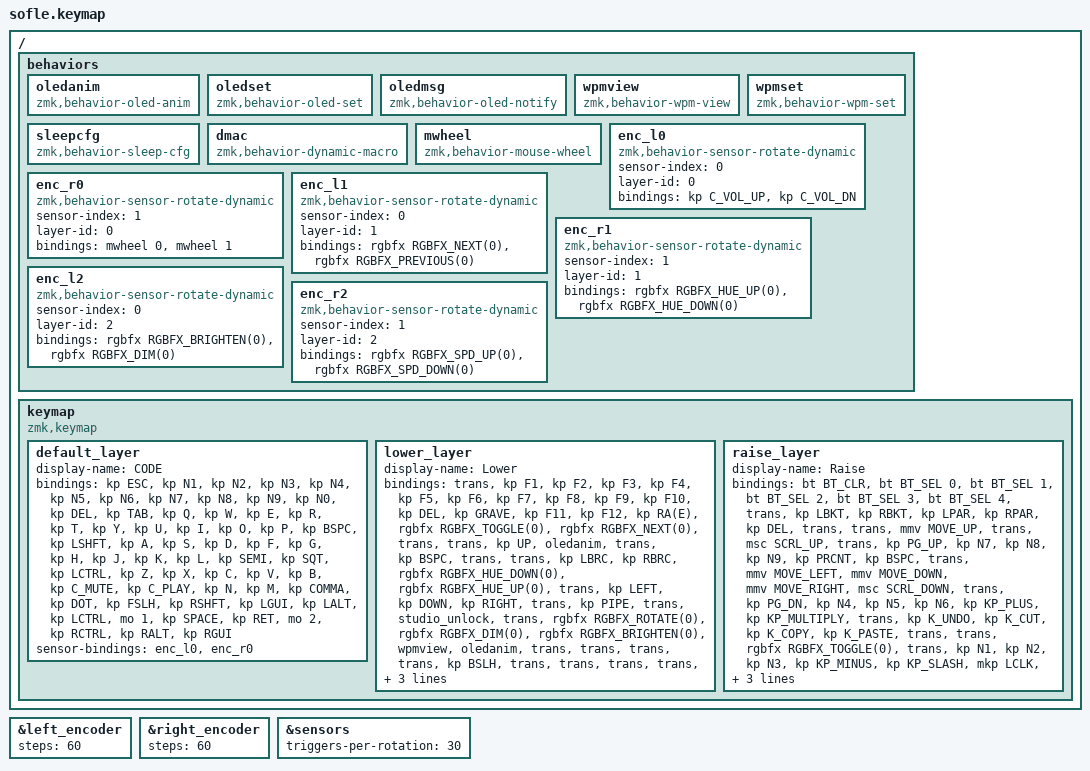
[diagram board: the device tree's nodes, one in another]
/*
 * Copyright (c) 2020 The ZMK Contributors
 *
 * SPDX-License-Identifier: MIT
 */

#include <behaviors.dtsi>
#include <dt-bindings/zmk/keys.h>
#include <dt-bindings/zmk/bt.h>
#include <dt-bindings/zmk/ext_power.h>
#include <dt-bindings/zmk/rgb_fx.h>
/* Raton por teclado (&mmv/&mkp/&msc). Vienen de serie en ZMK con
   CONFIG_ZMK_POINTING, que ya esta activo para la rueda del encoder. */
#include <dt-bindings/zmk/pointing.h>

/*
 * Same layout as the Choc variant (codekeeb/sofle-choc-rgb-zmk):
 * 3 layers, RGB controls on LOWER (left half) and on the encoders
 * (lower = mode/hue, raise = brightness/speed), numpad on RAISE.
 *
 * Unlike the Choc, NO led_strip/spi3 override is needed here: the MX PCB
 * uses P0.06 with a 36-LED chain, which matches what the official sofle
 * shield already sets.
 */

/ {
    behaviors {
        // Cycles the right OLED animation (gem/cat/head/spaceman/pokemon/logo)
        oledanim: oledanim {
            compatible = "zmk,behavior-oled-anim";
            #binding-cells = <0>;
        };

        // Relay interno central->periferico: fija la animacion por
        // indice. No se pone en ninguna tecla; lo invoca el handler RPC
        // de ZMK Studio, igual que el RGB usa &rgbsync. Sin esto, la web
        // cambiaba la animacion solo en la mitad central, que no tiene
        // la pantalla animada, y no se veia nada.
        oledset: oledset {
            compatible = "zmk,behavior-oled-set";
            #binding-cells = <1>;
        };

        // Internal central->peripheral relay: a notice (BT profile, BT
        // clear, USB/BLE, Caps Lock, Studio) for the right screen. Not
        // bound to any key; see src/oled_notify.c.
        oledmsg: oledmsg {
            compatible = "zmk,behavior-oled-notify";
            #binding-cells = <1>;
        };

        // Vista de WPM de la pantalla IZQUIERDA (bongo cat, luna,
        // numero, velocimetro, grafico). &wpmview cicla; &wpmset la
        // fija por indice y lo usa el RPC de ZMK Studio.
        wpmview: wpmview {
            compatible = "zmk,behavior-wpm-view";
            #binding-cells = <0>;
        };

        wpmset: wpmset {
            compatible = "zmk,behavior-wpm-set";
            #binding-cells = <1>;
        };

        // Relay interno central->periferico del ajuste de deep sleep
        // (activado + minutos). Como &oledset, no va en ninguna tecla:
        // lo invoca el handler RPC. Hace falta porque cada mitad vigila
        // su propia inactividad, asi que el ajuste hay que llevarlo a
        // las dos o el periferico se queda con el plazo viejo.
        sleepcfg: sleepcfg {
            compatible = "zmk,behavior-sleep-cfg";
            #binding-cells = <2>;
        };

        // Macros editables en caliente (CODEKEEB PATCH, ver
        // src/behaviors/behavior_dynamic_macro.c). &dmac N reproduce la
        // ranura N, cuyo contenido se escribe desde el editor web y vive
        // en flash: sirve para ñ, tildes, un email, "→"... sin recompilar.
        dmac: dmac {
            compatible = "zmk,behavior-dynamic-macro";
            #binding-cells = <1>;
        };

        // Discrete mouse wheel (CODEKEEB PATCH, see
        // src/behaviors/behavior_mouse_wheel.c). One HID wheel tick per
        // press: &mwheel 0 = up, 1 = down, 2 = left, 3 = right. Unlike
        // ZMK's stock &msc this works when fired from an encoder.
        mwheel: mwheel {
            compatible = "zmk,behavior-mouse-wheel";
            #binding-cells = <1>;
        };

        // Encoder rotation bindings below use zmk,behavior-sensor-rotate-dynamic
        // (CODEKEEB PATCH, see src/behaviors/behavior_sensor_rotate_dynamic.c)
        // instead of the stock zmk,behavior-sensor-rotate: same tap-dispatch
        // mechanism, but the cw/ccw pair is readable and rewritable at
        // runtime over ZMK Studio (persisted in flash), one instance per
        // (layer, encoder) combination. `bindings` below is only the
        // factory/default pair -- editing it live doesn't touch this file.
        // sensor-index: 0 = left encoder, 1 = right encoder.
        // layer-id: matches this keymap's declaration order (no layer
        // reordering used), 0 = CODE, 1 = Lower, 2 = Raise.

        enc_l0: enc_l0 { // CODE layer, left encoder: volume (factory)
            compatible = "zmk,behavior-sensor-rotate-dynamic";
            #sensor-binding-cells = <0>;
            sensor-index = <0>;
            layer-id = <0>;
            bindings = <&kp C_VOL_UP>, <&kp C_VOL_DN>;
        };

        enc_r0: enc_r0 { // CODE layer, right encoder: mouse wheel (factory)
            compatible = "zmk,behavior-sensor-rotate-dynamic";
            #sensor-binding-cells = <0>;
            sensor-index = <1>;
            layer-id = <0>;
            bindings = <&mwheel 0>, <&mwheel 1>;
        };

        enc_l1: enc_l1 { // Lower layer, left encoder: RGB mode (factory)
            compatible = "zmk,behavior-sensor-rotate-dynamic";
            #sensor-binding-cells = <0>;
            sensor-index = <0>;
            layer-id = <1>;
            bindings = <&rgbfx RGBFX_NEXT(0)>, <&rgbfx RGBFX_PREVIOUS(0)>;
        };

        enc_r1: enc_r1 { // Lower layer, right encoder: RGB hue (factory)
            compatible = "zmk,behavior-sensor-rotate-dynamic";
            #sensor-binding-cells = <0>;
            sensor-index = <1>;
            layer-id = <1>;
            bindings = <&rgbfx RGBFX_HUE_UP(0)>, <&rgbfx RGBFX_HUE_DOWN(0)>;
        };

        enc_l2: enc_l2 { // Raise layer, left encoder: RGB brightness (factory)
            compatible = "zmk,behavior-sensor-rotate-dynamic";
            #sensor-binding-cells = <0>;
            sensor-index = <0>;
            layer-id = <2>;
            bindings = <&rgbfx RGBFX_BRIGHTEN(0)>, <&rgbfx RGBFX_DIM(0)>;
        };

        enc_r2: enc_r2 { // Raise layer, right encoder: RGB speed (factory)
            compatible = "zmk,behavior-sensor-rotate-dynamic";
            #sensor-binding-cells = <0>;
            sensor-index = <1>;
            layer-id = <2>;
            bindings = <&rgbfx RGBFX_SPD_UP(0)>, <&rgbfx RGBFX_SPD_DOWN(0)>;
        };
    };

    keymap {
        compatible = "zmk,keymap";

        default_layer {
            display-name = "CODE";
// ------------------------------------------------------------------------------------------------------------------
// |  ESC  |  1  |  2  |  3   |  4   |  5   |                         |  6   |  7    |  8    |  9   |   0   |  DEL  |
// |  TAB  |  Q  |  W  |  E   |  R   |  T   |                         |  Y   |  U    |  I    |  O   |   P   | BKSPC |
// | SHIFT |  A  |  S  |  D   |  F   |  G   |                         |  H   |  J    |  K    |  L   |   ;   |   '   |
// |  CTRL |  Z  |  X  |  C   |  V   |  B   |  MUTE  |        | PLAY  |  N   |  M    |  ,    |  .   |   /   | SHIFT |
//               | GUI | ALT  | CTRL | LOWER|  SPACE |        | ENTER | RAISE| CTRL  | ALT   | GUI  |
            bindings = <
&kp ESC   &kp N1 &kp N2   &kp N3   &kp N4    &kp N5                              &kp N6 &kp N7    &kp N8    &kp N9   &kp N0   &kp DEL
&kp TAB   &kp Q  &kp W    &kp E    &kp R     &kp T                               &kp Y  &kp U     &kp I     &kp O    &kp P    &kp BSPC
&kp LSHFT &kp A  &kp S    &kp D    &kp F     &kp G                               &kp H  &kp J     &kp K     &kp L    &kp SEMI &kp SQT
&kp LCTRL &kp Z  &kp X    &kp C    &kp V     &kp B  &kp C_MUTE       &kp C_PLAY  &kp N  &kp M     &kp COMMA &kp DOT  &kp FSLH &kp RSHFT
                 &kp LGUI &kp LALT &kp LCTRL &mo 1  &kp SPACE        &kp RET     &mo 2  &kp RCTRL &kp RALT  &kp RGUI
            >;

            // Right encoder: real mouse wheel, one HID tick per detent
            // (&mwheel). ZMK's stock &msc can NOT be used here: it only
            // emits from its own delayed work loop and needs the press
            // held across several cycles, while sensor-rotate fires a
            // short tap -- USB logging confirmed zero reports at any
            // tap-ms. behavior_mouse_wheel.c sends one complete wheel
            // event per press instead, which is what a wheel detent
            // actually is. Both slots stay editable live from ZMK Studio
            // (see enc_l0/enc_r0 above).
            sensor-bindings = <&enc_l0 &enc_r0>;
        };

        lower_layer {
            display-name = "Lower";
// TODO: Some binds are waiting for shifted keycode support.
// ------------------------------------------------------------------------------------------------------------
// |       | F1  | F2  |  F3  |  F4  |  F5  |                         |  F6  |   F7  |   F8  |  F9  |  F10  |  DEL  |
// | `     | F11 | F12 |   €  | RGB  |modRGB|                         |      |       |   UP  |OLEDanim|       | BKSPC |
// |       |     |  {  |   }  | hue- | hue+ |                         |      | LEFT  |  DOWN | RIGHT|       |   |   |
// |       |ZMKSt|     |RGBrot| Bri- | Bri+ |WPMview |        |OLEDanim|     |       |       |      |   \   |       |
//               |     |      |      |      |  SPACE |        | ENTER |      |       |       |      |
            bindings = <
&trans     &kp F1         &kp F2       &kp F3       &kp F4                   &kp F5                                                         &kp F6     &kp F7     &kp F8           &kp F9     &kp F10    &kp DEL
&kp GRAVE  &kp F11        &kp F12      &kp RA(E)    &rgbfx RGBFX_TOGGLE(0)   &rgbfx RGBFX_NEXT(0)                                           &trans     &trans     &kp UP           &oledanim  &trans     &kp BSPC
&trans     &trans         &kp LBRC     &kp RBRC     &rgbfx RGBFX_HUE_DOWN(0) &rgbfx RGBFX_HUE_UP(0)                                         &trans     &kp LEFT   &kp DOWN         &kp RIGHT  &trans     &kp PIPE
&trans     &studio_unlock &trans       &rgbfx RGBFX_ROTATE(0) &rgbfx RGBFX_DIM(0)      &rgbfx RGBFX_BRIGHTEN(0)  &wpmview                  &oledanim  &trans     &trans     &trans           &trans     &kp BSLH   &trans
                          &trans       &trans       &trans                   &trans                    &trans                    &trans     &trans     &trans     &trans           &trans
            >;

            sensor-bindings = <&enc_l1 &enc_r1>;
        };

        raise_layer {
            display-name = "Raise";
// ------------------------------------------------------------------------------------------------------------
// |BTCLR| BT1  |  BT2 |  BT3  |  BT4  |  BT5 |                       |      |   [  |    ]  |   (  |   )   |  DEL  |
// |     |      | M↑   |       | scr↑  |      |                       | PGUP |   7  |    8  |   9  |   %   | BKSPC |
// |     | M←   | M↓   |  M→   | scr↓  |      |                       | PGDN |   4  |    5  |   6  |   +   |   x   |
// |     | UNDO | CUT  | COPY  | PASTE |      |       |        |  RGB |      |   1  |    2  |   3  |   -   |   /   |
//              | LCLK | MCLK  | RCLK  |      | SPACE |        | ENTER|      |   0  |    .  |   =  |
            bindings = <
&bt BT_CLR &bt BT_SEL 0 &bt BT_SEL 1 &bt BT_SEL 2 &bt BT_SEL 3 &bt BT_SEL 4                        &trans    &kp LBKT  &kp RBKT &kp LPAR  &kp RPAR      &kp DEL
&trans     &trans       &mmv MOVE_UP &trans       &msc SCRL_UP &trans                              &kp PG_UP &kp N7    &kp N8   &kp N9    &kp PRCNT     &kp BSPC
&trans     &mmv MOVE_LEFT &mmv MOVE_DOWN &mmv MOVE_RIGHT &msc SCRL_DOWN &trans                     &kp PG_DN &kp N4    &kp N5   &kp N6    &kp KP_PLUS   &kp KP_MULTIPLY
&trans     &kp K_UNDO   &kp K_CUT    &kp K_COPY   &kp K_PASTE  &trans  &trans   &rgbfx RGBFX_TOGGLE(0)  &trans    &kp N1   &kp N2    &kp N3        &kp KP_MINUS  &kp KP_SLASH
                        &mkp LCLK    &mkp MCLK    &mkp RCLK    &trans  &trans   &trans           &kp N0    &kp KP_DOT &kp KP_EQUAL &trans
            >;

            sensor-bindings = <&enc_l2 &enc_r2>;
        };
    };
};

/* CODEKEEB PATCH: make every encoder detent fire one rotation event.
 *
 * These are generic 30-detent encoders, not the 20-detent Alps EC11 the
 * Sofle shield assumes (steps=80, triggers-per-rotation=20). What decides
 * when an event fires is the ratio steps/triggers-per-rotation, i.e. how
 * many quadrature pulses the driver wants per event: 80/20 asks for 4,
 * but a USB trace of the real hardware shows each detent produces exactly
 * 2 transitions (clean, no bounce, no invalid states), so one event only
 * landed every other click. 60/30 asks for 2 => one detent, one event.
 *
 * This lives in the keymap, NOT in config/sofle_left.overlay, because the
 * user overlay is processed BEFORE the shield's own sofle_left.overlay,
 * which then overwrites these properties right back to 80/20. The keymap
 * is applied after the shield, so it is the one that actually wins.
 * Verified in the generated devicetree, not just assumed. */
&left_encoder {
    steps = <60>;
};

&right_encoder {
    steps = <60>;
};

&sensors {
    triggers-per-rotation = <30>;
};
